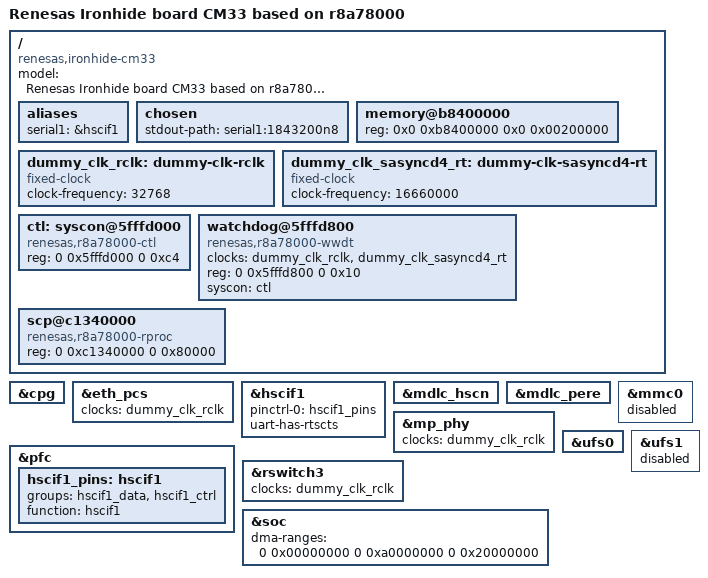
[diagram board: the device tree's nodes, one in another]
// SPDX-License-Identifier: (GPL-2.0-only OR BSD-2-Clause)
/*
 * Device Tree Source extras for U-Boot for the Ironhide CM33 board
 *
 * Copyright (C) 2026 Renesas Electronics Corp.
 */

#include "r8a78000-ironhide-u-boot.dtsi"

/ {
	model = "Renesas Ironhide board CM33 based on r8a78000";
	compatible = "renesas,ironhide-cm33", "renesas,r8a78000-cm33";

	aliases {
		serial1 = &hscif1;
	};

	chosen {
		stdout-path = "serial1:1843200n8";
	};

	/delete-node/ firmware;
	/delete-node/ memory@40000000;
	/delete-node/ memory@60600000;
	/delete-node/ memory@1080000000;
	/delete-node/ memory@1200000000;
	/delete-node/ memory@1400000000;
	/delete-node/ memory@1600000000;
	/delete-node/ memory@1800000000;
	/delete-node/ memory@1a00000000;
	/delete-node/ memory@1c00000000;
	/delete-node/ memory@1e00000000;
	/delete-node/ reserved-memory;

	memory@b8400000 {
		device_type = "memory";
		reg = <0x0 0xb8400000 0x0 0x00200000>;
	};

	dummy_clk_rclk: dummy-clk-rclk {
		compatible = "fixed-clock";
		#clock-cells = <0>;
		clock-frequency = <32768>;
	};

	dummy_clk_sasyncd4_rt: dummy-clk-sasyncd4-rt {
		compatible = "fixed-clock";
		#clock-cells = <0>;
		clock-frequency = <16660000>;
	};

	ctl: syscon@5fffd000 {
		compatible = "renesas,r8a78000-ctl",
			     "renesas,rcar-gen5-ctl",
			     "syscon";
		reg = <0 0x5fffd000 0 0xc4>;
	};

	watchdog@5fffd800 {
		compatible = "renesas,r8a78000-wwdt",
			     "renesas,rcar-gen5-wwdt";
		clocks = <&dummy_clk_rclk>, <&dummy_clk_sasyncd4_rt>;
		clock-names = "cnt", "bus";
		reg = <0 0x5fffd800 0 0x10>;
		syscon = <&ctl>;
	};

	scp@c1340000 {
		compatible = "renesas,r8a78000-rproc";
		reg = <0 0xc1340000 0 0x80000>;
	};
};

&cpg {
	/delete-property/ firmware;
};

&eth_pcs {
	/* Stub clock */
	clocks = <&dummy_clk_rclk>;
};

&hscif1 {
	pinctrl-0 = <&hscif1_pins>;
	pinctrl-names = "default";
	uart-has-rtscts;
	status = "okay";
};

&mdlc_hscn {
	/delete-property/ firmware;
};

&mdlc_pere {
	/delete-property/ firmware;
};

&mmc0 {
	status = "disabled";
};

&mp_phy {
	/* Stub clock */
	clocks = <&dummy_clk_rclk>;
};

&pfc {
	hscif1_pins: hscif1 {
		groups = "hscif1_data", "hscif1_ctrl";
		function = "hscif1";
	};
};

&rswitch3 {
	/* Stub clock */
	clocks = <&dummy_clk_rclk>;
};

&soc {
	dma-ranges = <0 0x00000000 0 0xa0000000 0 0x20000000>;
};

&ufs0 {
	/delete-property/ power-domains;
};

&ufs1 {
	/delete-property/ power-domains;
	status = "disabled";
};
